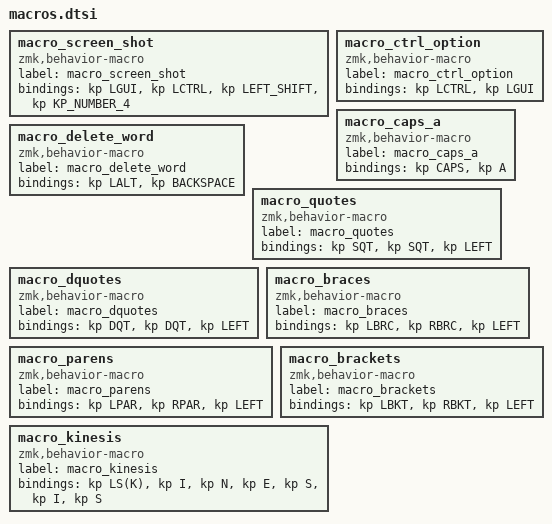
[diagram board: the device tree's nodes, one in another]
macro_screen_shot: macro_screen_shot{
compatible = "zmk,behavior-macro";
label = "macro_screen_shot";
#binding-cells = <0>;
bindings = <&kp LGUI>, <&kp LCTRL>, <&kp LEFT_SHIFT>, <&kp KP_NUMBER_4>;
};
macro_ctrl_option: macro_ctrl_option{
compatible = "zmk,behavior-macro";
label = "macro_ctrl_option";
#binding-cells = <0>;
bindings = <&kp LCTRL>, <&kp LGUI>;
};
macro_delete_word: macro_delete_word{
compatible = "zmk,behavior-macro";
label = "macro_delete_word";
#binding-cells = <0>;
bindings = <&kp LALT>, <&kp BACKSPACE>;
};
macro_caps_a: macro_caps_a{
compatible = "zmk,behavior-macro";
label = "macro_caps_a";
#binding-cells = <0>;
bindings = <&kp CAPS>, <&kp A>;
};
macro_quotes: macro_quotes{
compatible = "zmk,behavior-macro";
label = "macro_quotes";
#binding-cells = <0>;
bindings = <&kp SQT>, <&kp SQT>, <&kp LEFT>;
};
macro_dquotes: macro_dquotes{
compatible = "zmk,behavior-macro";
label = "macro_dquotes";
#binding-cells = <0>;
bindings = <&kp DQT>, <&kp DQT>, <&kp LEFT>;
};
macro_braces: macro_braces{
compatible = "zmk,behavior-macro";
label = "macro_braces";
#binding-cells = <0>;
bindings = <&kp LBRC>, <&kp RBRC>, <&kp LEFT>;
};
macro_parens: macro_parens{
compatible = "zmk,behavior-macro";
label = "macro_parens";
#binding-cells = <0>;
bindings = <&kp LPAR>, <&kp RPAR>, <&kp LEFT>;
};
macro_brackets: macro_brackets{
compatible = "zmk,behavior-macro";
label = "macro_brackets";
#binding-cells = <0>;
bindings = <&kp LBKT>, <&kp RBKT>, <&kp LEFT>;
};
macro_kinesis: macro_kinesis{
compatible = "zmk,behavior-macro";
label = "macro_kinesis";
#binding-cells = <0>;
bindings = <&kp LS(K)>, <&kp I>, <&kp N>, <&kp E>, <&kp S>, <&kp I>, <&kp S>;
};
